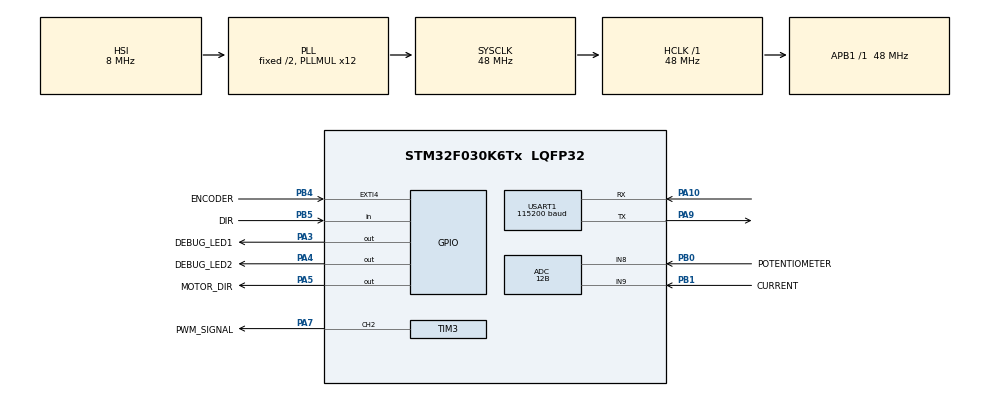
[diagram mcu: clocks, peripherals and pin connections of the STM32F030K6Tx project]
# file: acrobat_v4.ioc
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ADC.ClockPrescaler=ADC_CLOCK_ASYNC_DIV1
ADC.ContinuousConvMode=ENABLE
ADC.DMAContinuousRequests=ENABLE
ADC.DataAlign=ADC_DATAALIGN_RIGHT
ADC.DiscontinuousConvMode=DISABLE
ADC.EOCSelection=ADC_EOC_SINGLE_CONV
ADC.EnableAnalogWatchDog=false
ADC.ExternalTrigConv=ADC_SOFTWARE_START
ADC.ExternalTrigConvEdge=ADC_EXTERNALTRIGCONVEDGE_NONE
ADC.LowPowerAutoPowerOff=DISABLE
ADC.LowPowerAutoWait=DISABLE
ADC.Overrun=ADC_OVR_DATA_PRESERVED
ADC.Resolution=ADC_RESOLUTION_12B
ADC.SamplingTime=ADC_SAMPLETIME_239CYCLES_5
ADC.ScanConvMode=ADC_SCAN_DIRECTION_FORWARD
Dma.ADC.1.Direction=DMA_PERIPH_TO_MEMORY
Dma.ADC.1.Instance=DMA1_Channel1
Dma.ADC.1.MemDataAlignment=DMA_MDATAALIGN_WORD
Dma.ADC.1.MemInc=DMA_MINC_ENABLE
Dma.ADC.1.Mode=DMA_CIRCULAR
Dma.ADC.1.PeriphDataAlignment=DMA_PDATAALIGN_WORD
Dma.ADC.1.PeriphInc=DMA_PINC_DISABLE
Dma.ADC.1.Priority=DMA_PRIORITY_HIGH
Dma.Request0=USART1_TX
Dma.Request1=ADC
Dma.USART1_TX.0.Direction=DMA_MEMORY_TO_PERIPH
Dma.USART1_TX.0.Instance=DMA1_Channel2
Dma.USART1_TX.0.MemDataAlignment=DMA_MDATAALIGN_BYTE
Dma.USART1_TX.0.MemInc=DMA_MINC_ENABLE
Dma.USART1_TX.0.Mode=DMA_NORMAL
Dma.USART1_TX.0.PeriphDataAlignment=DMA_PDATAALIGN_BYTE
Dma.USART1_TX.0.PeriphInc=DMA_PINC_DISABLE
Dma.USART1_TX.0.Priority=DMA_PRIORITY_HIGH
Mcu.Family=STM32F0
Mcu.Name=STM32F030K6Tx
Mcu.Package=LQFP32
NVIC.DMA1_Channel1_IRQn=true\:1\:0\:true\:false\:true\:false
NVIC.DMA1_Channel2_3_IRQn=true\:1\:0\:true\:false\:true\:false
NVIC.EXTI4_15_IRQn=true\:0\:0\:false\:false\:true\:true
NVIC.TIM14_IRQn=true\:1\:0\:true\:false\:true\:true
NVIC.TIM3_IRQn=true\:1\:0\:true\:false\:true\:true
NVIC.USART1_IRQn=true\:0\:0\:false\:false\:true\:true
PA10.Mode=Asynchronous
PA10.Signal=USART1_RX
PA13.Mode=Serial_Wire
PA13.Signal=SYS_SWDIO
PA14.Mode=Serial_Wire
PA14.Signal=SYS_SWCLK
PA3.GPIO_Label=DEBUG_LED1
PA3.Signal=GPIO_Output
PA4.GPIO_Label=DEBUG_LED2
PA4.Signal=GPIO_Output
PA5.GPIO_Label=MOTOR_DIR
PA5.Signal=GPIO_Output
PA7.GPIO_Label=PWM_SIGNAL
PA7.Signal=S_TIM3_CH2
PA9.Mode=Asynchronous
PA9.Signal=USART1_TX
PB0.GPIO_Label=POTENTIOMETER
PB0.Mode=IN8
PB0.Signal=ADC_IN8
PB1.GPIO_Label=CURRENT
PB1.Mode=IN9
PB1.Signal=ADC_IN9
PB4.GPIO_Label=ENCODER
PB4.GPIO_ModeDefaultEXTI=GPIO_MODE_IT_RISING_FALLING
PB4.Signal=GPXTI4
PB5.GPIO_Label=DIR
PB5.Signal=GPIO_Input
ProjectManager.HeapSize=0x200
ProjectManager.StackSize=0x400
ProjectManager.TargetToolchain=TrueSTUDIO
RCC.AHBFreq_Value=48000000
RCC.APB1Freq_Value=48000000
RCC.APB1TimFreq_Value=48000000
RCC.HCLKFreq_Value=48000000
RCC.PLLMUL=RCC_PLL_MUL12
RCC.SYSCLKFreq_VALUE=48000000
RCC.SYSCLKSource=RCC_SYSCLKSOURCE_PLLCLK
SH.S_TIM3_CH2.0=TIM3_CH2,PWM Generation2 CH2
TIM14.Period=500
TIM14.Prescaler=192
TIM3.AutoReloadPreload=TIM_AUTORELOAD_PRELOAD_DISABLE
TIM3.Channel-PWM\ Generation2\ CH2=TIM_CHANNEL_2
TIM3.Period=99
TIM3.Prescaler=48
USART1.BaudRate=115200
USART1.VirtualMode-Asynchronous=VM_ASYNC
VP_TIM14_VS_ClockSourceINT.Mode=Enable_Timer
board=acrobat_v4

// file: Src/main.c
/**
  ******************************************************************************
  * @file           : main.c
  * @brief          : Main program body
  ******************************************************************************
  ** This notice applies to any and all portions of this file
  * that are not between comment pairs USER CODE BEGIN and
  * USER CODE END. Other portions of this file, whether
  * inserted by the user or by software development tools
  * are owned by their respective copyright owners.
  *
  * COPYRIGHT(c) 2018 STMicroelectronics
  *
  * Redistribution and use in source and binary forms, with or without modification,
  * are permitted provided that the following conditions are met:
  *   1. Redistributions of source code must retain the above copyright notice,
  *      this list of conditions and the following disclaimer.
  *   2. Redistributions in binary form must reproduce the above copyright notice,
  *      this list of conditions and the following disclaimer in the documentation
  *      and/or other materials provided with the distribution.
  *   3. Neither the name of STMicroelectronics nor the names of its contributors
  *      may be used to endorse or promote products derived from this software
  *      without specific prior written permission.
  *
  * THIS SOFTWARE IS PROVIDED BY THE COPYRIGHT HOLDERS AND CONTRIBUTORS "AS IS"
  * AND ANY EXPRESS OR IMPLIED WARRANTIES, INCLUDING, BUT NOT LIMITED TO, THE
  * IMPLIED WARRANTIES OF MERCHANTABILITY AND FITNESS FOR A PARTICULAR PURPOSE ARE
  * DISCLAIMED. IN NO EVENT SHALL THE COPYRIGHT HOLDER OR CONTRIBUTORS BE LIABLE
  * FOR ANY DIRECT, INDIRECT, INCIDENTAL, SPECIAL, EXEMPLARY, OR CONSEQUENTIAL
  * DAMAGES (INCLUDING, BUT NOT LIMITED TO, PROCUREMENT OF SUBSTITUTE GOODS OR
  * SERVICES; LOSS OF USE, DATA, OR PROFITS; OR BUSINESS INTERRUPTION) HOWEVER
  * CAUSED AND ON ANY THEORY OF LIABILITY, WHETHER IN CONTRACT, STRICT LIABILITY,
  * OR TORT (INCLUDING NEGLIGENCE OR OTHERWISE) ARISING IN ANY WAY OUT OF THE USE
  * OF THIS SOFTWARE, EVEN IF ADVISED OF THE POSSIBILITY OF SUCH DAMAGE.
  *
  ******************************************************************************
  */
#include "main.h"
#include "stm32f0xx_hal.h"

/* USER CODE BEGIN Includes */
#include "function.h"
#include "variables.h"
/* USER CODE END Includes */

ADC_HandleTypeDef hadc;
DMA_HandleTypeDef hdma_adc;

TIM_HandleTypeDef htim3;
TIM_HandleTypeDef htim14;

UART_HandleTypeDef huart1;
DMA_HandleTypeDef hdma_usart1_tx;

/* USER CODE BEGIN PV */
/* Private variables ---------------------------------------------------------*/

/* USER CODE END PV */

void SystemClock_Config(void);
static void MX_GPIO_Init(void);
static void MX_DMA_Init(void);
static void MX_ADC_Init(void);
static void MX_USART1_UART_Init(void);
static void MX_TIM3_Init(void);
static void MX_TIM14_Init(void);

void HAL_TIM_MspPostInit(TIM_HandleTypeDef *htim);

/* USER CODE BEGIN PFP */
/* Private function prototypes -----------------------------------------------*/

/* USER CODE END PFP */

int main(void)
{

  /* MCU Configuration----------------------------------------------------------*/

  /* Reset of all peripherals, Initializes the Flash interface and the Systick. */
  HAL_Init();

  /* Configure the system clock */
  SystemClock_Config();

  /* Initialize all configured peripherals */
  MX_GPIO_Init();
  MX_DMA_Init();
  MX_ADC_Init();
  MX_USART1_UART_Init();
  MX_TIM3_Init();
  MX_TIM14_Init();
  /* USER CODE BEGIN 2 */
  init_variables();
  startPeripherals();
 // discretize_arctan();
  /* USER CODE END 2 */

  /* Infinite loop */
  while (1)
  {

  /* USER CODE BEGIN 3 */
	  user_main();
  }
  /* USER CODE END 3 */

}

void SystemClock_Config(void)
{

  RCC_OscInitTypeDef RCC_OscInitStruct;
  RCC_ClkInitTypeDef RCC_ClkInitStruct;
  RCC_PeriphCLKInitTypeDef PeriphClkInit;

    /**Initializes the CPU, AHB and APB busses clocks
    */
  RCC_OscInitStruct.OscillatorType = RCC_OSCILLATORTYPE_HSI|RCC_OSCILLATORTYPE_HSI14;
  RCC_OscInitStruct.HSIState = RCC_HSI_ON;
  RCC_OscInitStruct.HSI14State = RCC_HSI14_ON;
  RCC_OscInitStruct.HSICalibrationValue = 16;
  RCC_OscInitStruct.HSI14CalibrationValue = 16;
  RCC_OscInitStruct.PLL.PLLState = RCC_PLL_ON;
  RCC_OscInitStruct.PLL.PLLSource = RCC_PLLSOURCE_HSI;
  RCC_OscInitStruct.PLL.PLLMUL = RCC_PLL_MUL12;
  RCC_OscInitStruct.PLL.PREDIV = RCC_PREDIV_DIV1;
  if (HAL_RCC_OscConfig(&RCC_OscInitStruct) != HAL_OK)
  {
    _Error_Handler(__FILE__, __LINE__);
  }

    /**Initializes the CPU, AHB and APB busses clocks
    */
  RCC_ClkInitStruct.ClockType = RCC_CLOCKTYPE_HCLK|RCC_CLOCKTYPE_SYSCLK
                              |RCC_CLOCKTYPE_PCLK1;
  RCC_ClkInitStruct.SYSCLKSource = RCC_SYSCLKSOURCE_PLLCLK;
  RCC_ClkInitStruct.AHBCLKDivider = RCC_SYSCLK_DIV1;
  RCC_ClkInitStruct.APB1CLKDivider = RCC_HCLK_DIV1;

  if (HAL_RCC_ClockConfig(&RCC_ClkInitStruct, FLASH_LATENCY_1) != HAL_OK)
  {
    _Error_Handler(__FILE__, __LINE__);
  }

  PeriphClkInit.PeriphClockSelection = RCC_PERIPHCLK_USART1;
  PeriphClkInit.Usart1ClockSelection = RCC_USART1CLKSOURCE_PCLK1;
  if (HAL_RCCEx_PeriphCLKConfig(&PeriphClkInit) != HAL_OK)
  {
    _Error_Handler(__FILE__, __LINE__);
  }

    /**Configure the Systick interrupt time
    */
  HAL_SYSTICK_Config(HAL_RCC_GetHCLKFreq()/1000);

    /**Configure the Systick
    */
  HAL_SYSTICK_CLKSourceConfig(SYSTICK_CLKSOURCE_HCLK);

  /* SysTick_IRQn interrupt configuration */
  HAL_NVIC_SetPriority(SysTick_IRQn, 0, 0);
}

/* ADC init function */
static void MX_ADC_Init(void)
{

  ADC_ChannelConfTypeDef sConfig;

    /**Configure the global features of the ADC (Clock, Resolution, Data Alignment and number of conversion)
    */
  hadc.Instance = ADC1;
  hadc.Init.ClockPrescaler = ADC_CLOCK_ASYNC_DIV1;
  hadc.Init.Resolution = ADC_RESOLUTION_12B;
  hadc.Init.DataAlign = ADC_DATAALIGN_RIGHT;
  hadc.Init.ScanConvMode = ADC_SCAN_DIRECTION_FORWARD;
  hadc.Init.EOCSelection = ADC_EOC_SINGLE_CONV;
  hadc.Init.LowPowerAutoWait = DISABLE;
  hadc.Init.LowPowerAutoPowerOff = DISABLE;
  hadc.Init.ContinuousConvMode = ENABLE;
  hadc.Init.DiscontinuousConvMode = DISABLE;
  hadc.Init.ExternalTrigConv = ADC_SOFTWARE_START;
  hadc.Init.ExternalTrigConvEdge = ADC_EXTERNALTRIGCONVEDGE_NONE;
  hadc.Init.DMAContinuousRequests = ENABLE;
  hadc.Init.Overrun = ADC_OVR_DATA_PRESERVED;
  if (HAL_ADC_Init(&hadc) != HAL_OK)
  {
    _Error_Handler(__FILE__, __LINE__);
  }

    /**Configure for the selected ADC regular channel to be converted.
    */
  sConfig.Channel = ADC_CHANNEL_8;
  sConfig.Rank = ADC_RANK_CHANNEL_NUMBER;
  sConfig.SamplingTime = ADC_SAMPLETIME_239CYCLES_5;
  if (HAL_ADC_ConfigChannel(&hadc, &sConfig) != HAL_OK)
  {
    _Error_Handler(__FILE__, __LINE__);
  }

    /**Configure for the selected ADC regular channel to be converted.
    */
  sConfig.Channel = ADC_CHANNEL_9;
  if (HAL_ADC_ConfigChannel(&hadc, &sConfig) != HAL_OK)
  {
    _Error_Handler(__FILE__, __LINE__);
  }

}

/* TIM3 init function */
static void MX_TIM3_Init(void)
{

  TIM_MasterConfigTypeDef sMasterConfig;
  TIM_OC_InitTypeDef sConfigOC;

  htim3.Instance = TIM3;
  htim3.Init.Prescaler = 48;
  htim3.Init.CounterMode = TIM_COUNTERMODE_UP;
  htim3.Init.Period = 99;
  htim3.Init.ClockDivision = TIM_CLOCKDIVISION_DIV1;
  htim3.Init.AutoReloadPreload = TIM_AUTORELOAD_PRELOAD_DISABLE;
  if (HAL_TIM_PWM_Init(&htim3) != HAL_OK)
  {
    _Error_Handler(__FILE__, __LINE__);
  }

  sMasterConfig.MasterOutputTrigger = TIM_TRGO_RESET;
  sMasterConfig.MasterSlaveMode = TIM_MASTERSLAVEMODE_DISABLE;
  if (HAL_TIMEx_MasterConfigSynchronization(&htim3, &sMasterConfig) != HAL_OK)
  {
    _Error_Handler(__FILE__, __LINE__);
  }

  sConfigOC.OCMode = TIM_OCMODE_PWM1;
  sConfigOC.Pulse = 0;
  sConfigOC.OCPolarity = TIM_OCPOLARITY_HIGH;
  sConfigOC.OCFastMode = TIM_OCFAST_DISABLE;
  if (HAL_TIM_PWM_ConfigChannel(&htim3, &sConfigOC, TIM_CHANNEL_2) != HAL_OK)
  {
    _Error_Handler(__FILE__, __LINE__);
  }

  HAL_TIM_MspPostInit(&htim3);

}

/* TIM14 init function */
static void MX_TIM14_Init(void)
{

  htim14.Instance = TIM14;
  htim14.Init.Prescaler = 192;
  htim14.Init.CounterMode = TIM_COUNTERMODE_UP;
  htim14.Init.Period = 500;
  htim14.Init.ClockDivision = TIM_CLOCKDIVISION_DIV1;
  htim14.Init.AutoReloadPreload = TIM_AUTORELOAD_PRELOAD_DISABLE;
  if (HAL_TIM_Base_Init(&htim14) != HAL_OK)
  {
    _Error_Handler(__FILE__, __LINE__);
  }

}

/* USART1 init function */
static void MX_USART1_UART_Init(void)
{

  huart1.Instance = USART1;
  huart1.Init.BaudRate = 115200;
  huart1.Init.WordLength = UART_WORDLENGTH_8B;
  huart1.Init.StopBits = UART_STOPBITS_1;
  huart1.Init.Parity = UART_PARITY_NONE;
  huart1.Init.Mode = UART_MODE_TX_RX;
  huart1.Init.HwFlowCtl = UART_HWCONTROL_NONE;
  huart1.Init.OverSampling = UART_OVERSAMPLING_16;
  huart1.Init.OneBitSampling = UART_ONE_BIT_SAMPLE_DISABLE;
  huart1.AdvancedInit.AdvFeatureInit = UART_ADVFEATURE_NO_INIT;
  if (HAL_UART_Init(&huart1) != HAL_OK)
  {
    _Error_Handler(__FILE__, __LINE__);
  }

}

static void MX_DMA_Init(void)
{
  /* DMA controller clock enable */
  __HAL_RCC_DMA1_CLK_ENABLE();

  /* DMA interrupt init */
  /* DMA1_Channel1_IRQn interrupt configuration */
  HAL_NVIC_SetPriority(DMA1_Channel1_IRQn, 1, 0);
  HAL_NVIC_EnableIRQ(DMA1_Channel1_IRQn);
  /* DMA1_Channel2_3_IRQn interrupt configuration */
  HAL_NVIC_SetPriority(DMA1_Channel2_3_IRQn, 1, 0);
  HAL_NVIC_EnableIRQ(DMA1_Channel2_3_IRQn);

}

/** Configure pins as
        * Analog
        * Input
        * Output
        * EVENT_OUT
        * EXTI
*/
static void MX_GPIO_Init(void)
{

  GPIO_InitTypeDef GPIO_InitStruct;

  /* GPIO Ports Clock Enable */
  __HAL_RCC_GPIOA_CLK_ENABLE();
  __HAL_RCC_GPIOB_CLK_ENABLE();

  /*Configure GPIO pin Output Level */
  HAL_GPIO_WritePin(GPIOA, DEBUG_LED1_Pin|DEBUG_LED2_Pin|MOTOR_DIR_Pin, GPIO_PIN_RESET);

  /*Configure GPIO pins : DEBUG_LED1_Pin DEBUG_LED2_Pin MOTOR_DIR_Pin */
  GPIO_InitStruct.Pin = DEBUG_LED1_Pin|DEBUG_LED2_Pin|MOTOR_DIR_Pin;
  GPIO_InitStruct.Mode = GPIO_MODE_OUTPUT_PP;
  GPIO_InitStruct.Pull = GPIO_NOPULL;
  GPIO_InitStruct.Speed = GPIO_SPEED_FREQ_LOW;
  HAL_GPIO_Init(GPIOA, &GPIO_InitStruct);

  /*Configure GPIO pin : ENCODER_Pin */
  GPIO_InitStruct.Pin = ENCODER_Pin;
  GPIO_InitStruct.Mode = GPIO_MODE_IT_RISING_FALLING;
  GPIO_InitStruct.Pull = GPIO_NOPULL;
  HAL_GPIO_Init(ENCODER_GPIO_Port, &GPIO_InitStruct);

  /*Configure GPIO pin : DIR_Pin */
  GPIO_InitStruct.Pin = DIR_Pin;
  GPIO_InitStruct.Mode = GPIO_MODE_INPUT;
  GPIO_InitStruct.Pull = GPIO_NOPULL;
  HAL_GPIO_Init(DIR_GPIO_Port, &GPIO_InitStruct);

  /* EXTI interrupt init*/
  HAL_NVIC_SetPriority(EXTI4_15_IRQn, 0, 0);
  HAL_NVIC_EnableIRQ(EXTI4_15_IRQn);

}

void _Error_Handler(char *file, int line)
{
  while(1)
  {
  }
}

/************************ (C) COPYRIGHT STMicroelectronics *****END OF FILE****/
